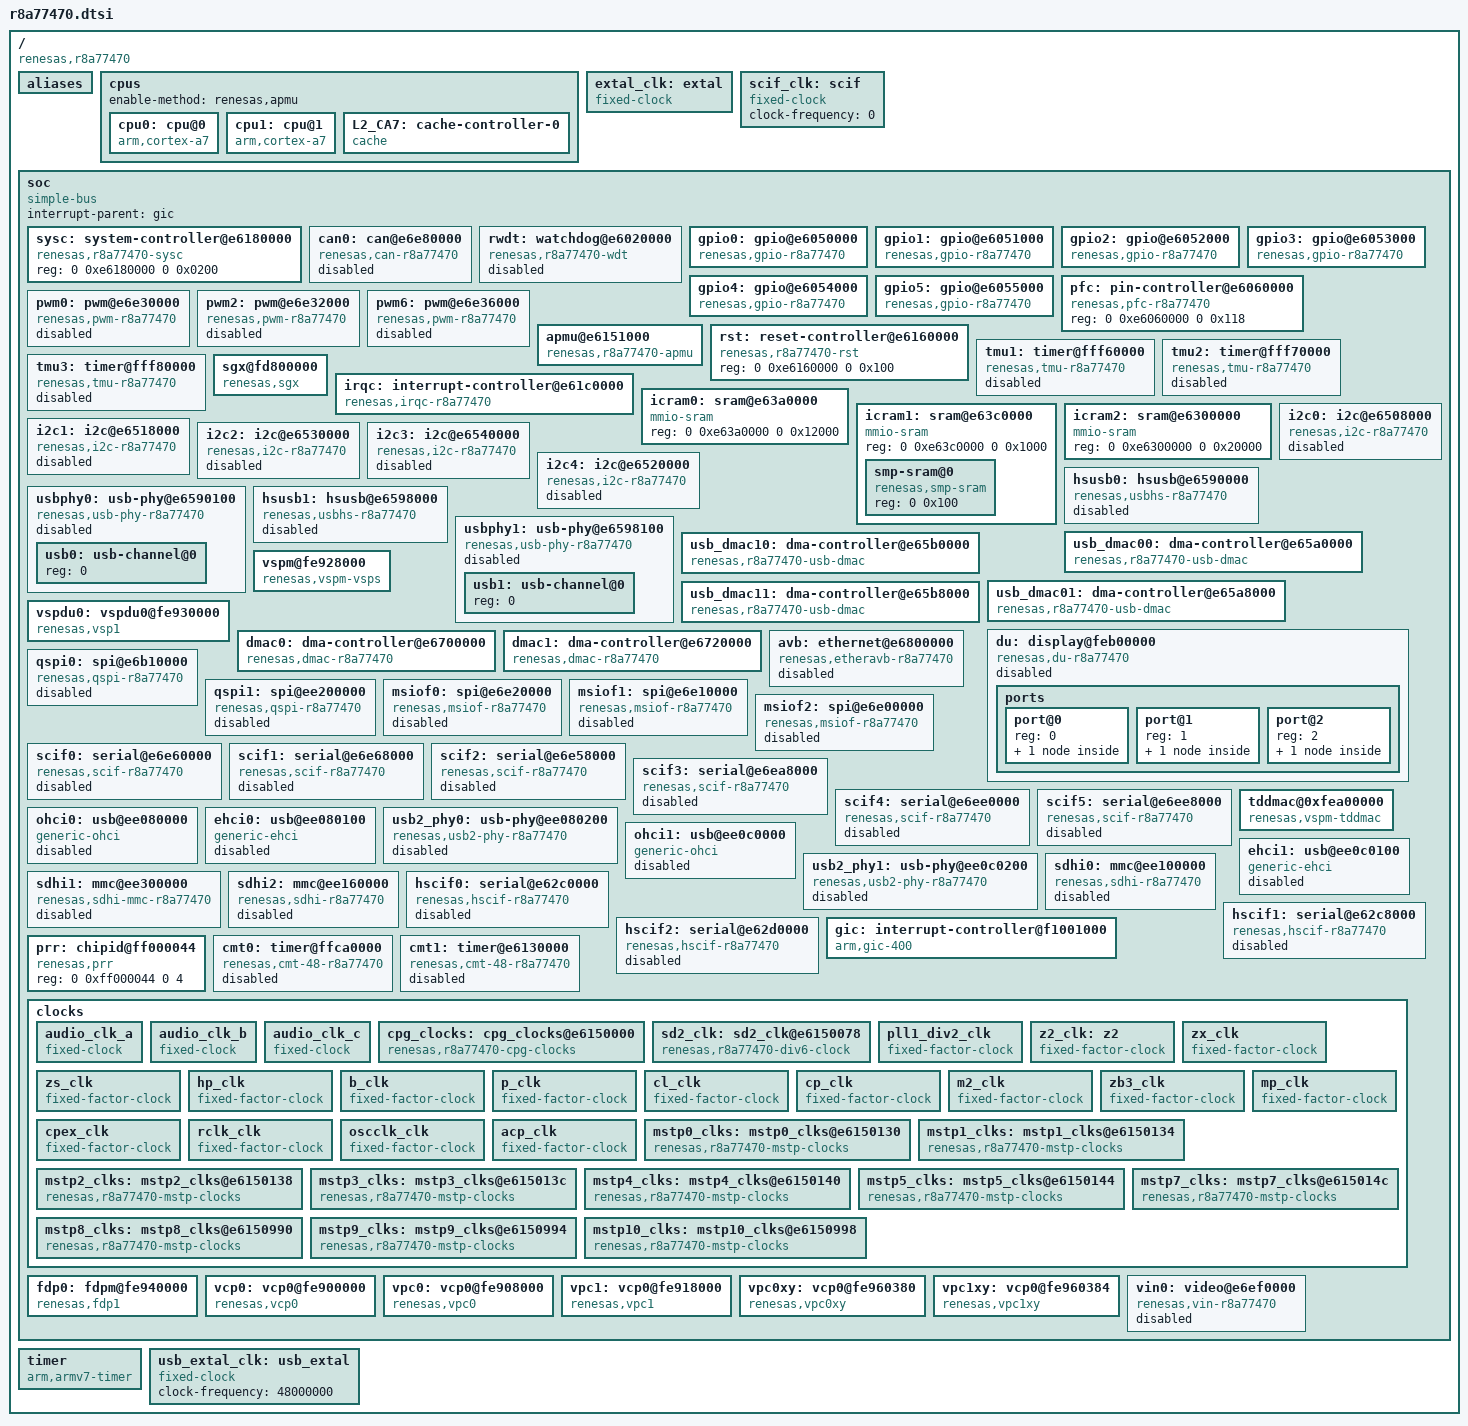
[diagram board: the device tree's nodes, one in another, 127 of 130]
// SPDX-License-Identifier: GPL-2.0
/*
 * Device Tree Source for the r8a77470 SoC
 *
 * Copyright (C) 2018 Renesas Electronics Corp.
 */

#include <dt-bindings/interrupt-controller/irq.h>
#include <dt-bindings/interrupt-controller/arm-gic.h>
#include <dt-bindings/clock/r8a77470-clock.h>
#include <dt-bindings/power/r8a77470-sysc.h>

/ {
	compatible = "renesas,r8a77470";
	#address-cells = <2>;
	#size-cells = <2>;

	aliases {
		i2c0 = &i2c0;
		i2c1 = &i2c1;
		i2c2 = &i2c2;
		i2c3 = &i2c3;
		i2c4 = &i2c4;
		spi0 = &qspi0;
		spi1 = &qspi1;
		spi2 = &msiof0;
		spi3 = &msiof1;
		spi4 = &msiof2;
		vin0 = &vin0;
	};

	cpus {
		#address-cells = <1>;
		#size-cells = <0>;
		enable-method = "renesas,apmu";

		cpu0: cpu@0 {
			device_type = "cpu";
			compatible = "arm,cortex-a7";
			reg = <0>;
			clock-frequency = <1000000000>;
			clocks = <&z2_clk>;
			power-domains = <&sysc R8A77470_PD_CA7_CPU0>;
			next-level-cache = <&L2_CA7>;
		};

		cpu1: cpu@1 {
			device_type = "cpu";
			compatible = "arm,cortex-a7";
			reg = <1>;
			clock-frequency = <1000000000>;
			clocks = <&z2_clk>;
			power-domains = <&sysc R8A77470_PD_CA7_CPU1>;
			next-level-cache = <&L2_CA7>;
		};

		L2_CA7: cache-controller-0 {
			compatible = "cache";
			cache-unified;
			cache-level = <2>;
		};
	};

	/* External root clock */
	extal_clk: extal {
		compatible = "fixed-clock";
		#clock-cells = <0>;
		/* This value must be overridden by the board. */
		clock-frequency = <0>;
		clock-output-names = "extal";
	};

	/* External SCIF clock */
	scif_clk: scif {
		compatible = "fixed-clock";
		#clock-cells = <0>;
		/* This value must be overridden by the board. */
		clock-frequency = <0>;
	};

	soc {
		compatible = "simple-bus";
		interrupt-parent = <&gic>;

		#address-cells = <2>;
		#size-cells = <2>;
		ranges;

		sysc: system-controller@e6180000 {
			compatible = "renesas,r8a77470-sysc";
			reg = <0 0xe6180000 0 0x0200>;
			#power-domain-cells = <1>;
		};

		can0: can@e6e80000 {
			compatible = "renesas,can-r8a77470";
			reg = <0 0xe6e80000 0 0x1000>;
			interrupts = <0 186 IRQ_TYPE_LEVEL_HIGH>;
			clocks = <&mstp9_clks R8A77470_CLK_CAN0>;
			clock-names = "clkp1";
			power-domains = <&sysc R8A77470_PD_ALWAYS_ON>;
			status = "disabled";
		};

		rwdt: watchdog@e6020000 {
			compatible = "renesas,r8a77470-wdt",
				     "renesas,rcar-gen2-wdt";
			reg = <0 0xe6020000 0 0x0c>;
			clocks = <&mstp4_clks R8A77470_CLK_RWDT>;
			power-domains = <&sysc R8A77470_PD_ALWAYS_ON>;
			status = "disabled";
		};

		gpio0: gpio@e6050000 {
			compatible = "renesas,gpio-r8a77470",
				     "renesas,rcar-gen2-gpio";
			reg = <0 0xe6050000 0 0x50>;
			interrupts = <GIC_SPI 4 IRQ_TYPE_LEVEL_HIGH>;
			#gpio-cells = <2>;
			gpio-controller;
			gpio-ranges = <&pfc 0 0 32>;
			#interrupt-cells = <2>;
			interrupt-controller;
			clocks = <&mstp9_clks R8A77470_CLK_GPIO0>;
			power-domains = <&sysc R8A77470_PD_ALWAYS_ON>;
		};

		gpio1: gpio@e6051000 {
			compatible = "renesas,gpio-r8a77470",
				     "renesas,rcar-gen2-gpio";
			reg = <0 0xe6051000 0 0x50>;
			interrupts = <GIC_SPI 5 IRQ_TYPE_LEVEL_HIGH>;
			#gpio-cells = <2>;
			gpio-controller;
			gpio-ranges = <&pfc 0 32 32>;
			#interrupt-cells = <2>;
			interrupt-controller;
			clocks = <&mstp9_clks R8A77470_CLK_GPIO1>;
			power-domains = <&sysc R8A77470_PD_ALWAYS_ON>;
		};

		gpio2: gpio@e6052000 {
			compatible = "renesas,gpio-r8a77470",
				     "renesas,rcar-gen2-gpio";
			reg = <0 0xe6052000 0 0x50>;
			interrupts = <GIC_SPI 6 IRQ_TYPE_LEVEL_HIGH>;
			#gpio-cells = <2>;
			gpio-controller;
			gpio-ranges = <&pfc 0 64 32>;
			#interrupt-cells = <2>;
			interrupt-controller;
			clocks = <&mstp9_clks R8A77470_CLK_GPIO2>;
			power-domains = <&sysc R8A77470_PD_ALWAYS_ON>;
		};

		gpio3: gpio@e6053000 {
			compatible = "renesas,gpio-r8a77470",
				     "renesas,rcar-gen2-gpio";
			reg = <0 0xe6053000 0 0x50>;
			interrupts = <GIC_SPI 7 IRQ_TYPE_LEVEL_HIGH>;
			#gpio-cells = <2>;
			gpio-controller;
			gpio-ranges = <&pfc 0 96 32>;
			gpio-reserved-ranges = <17 10>;
			#interrupt-cells = <2>;
			interrupt-controller;
			clocks = <&mstp9_clks R8A77470_CLK_GPIO3>;
			power-domains = <&sysc R8A77470_PD_ALWAYS_ON>;
		};

		gpio4: gpio@e6054000 {
			compatible = "renesas,gpio-r8a77470",
				     "renesas,rcar-gen2-gpio";
			reg = <0 0xe6054000 0 0x50>;
			interrupts = <GIC_SPI 8 IRQ_TYPE_LEVEL_HIGH>;
			#gpio-cells = <2>;
			gpio-controller;
			gpio-ranges = <&pfc 0 128 32>;
			#interrupt-cells = <2>;
			interrupt-controller;
			clocks = <&mstp9_clks R8A77470_CLK_GPIO4>;
			power-domains = <&sysc R8A77470_PD_ALWAYS_ON>;
		};

		gpio5: gpio@e6055000 {
			compatible = "renesas,gpio-r8a77470",
				     "renesas,rcar-gen2-gpio";
			reg = <0 0xe6055000 0 0x50>;
			interrupts = <GIC_SPI 9 IRQ_TYPE_LEVEL_HIGH>;
			#gpio-cells = <2>;
			gpio-controller;
			gpio-ranges = <&pfc 0 160 32>;
			#interrupt-cells = <2>;
			interrupt-controller;
			clocks = <&mstp9_clks R8A77470_CLK_GPIO5>;
			power-domains = <&sysc R8A77470_PD_ALWAYS_ON>;
		};

		pfc: pin-controller@e6060000 {
			compatible = "renesas,pfc-r8a77470";
			reg = <0 0xe6060000 0 0x118>;
		};

		pwm0: pwm@e6e30000 {
			compatible = "renesas,pwm-r8a77470";
			reg = <0 0xe6e30000 0 0x8>;
			#pwm-cells = <2>;
			clocks = <&mstp5_clks R8A77470_CLK_PWM>;
			power-domains = <&sysc R8A77470_PD_ALWAYS_ON>;
			status = "disabled";
		};

		pwm2: pwm@e6e32000 {
			compatible = "renesas,pwm-r8a77470";
			reg = <0 0xe6e32000 0 0x8>;
			#pwm-cells = <2>;
			clocks = <&mstp5_clks R8A77470_CLK_PWM>;
			power-domains = <&sysc R8A77470_PD_ALWAYS_ON>;
			status = "disabled";
		};

		pwm6: pwm@e6e36000 {
			compatible = "renesas,pwm-r8a77470";
			reg = <0 0xe6e36000 0 0x8>;
			#pwm-cells = <2>;
			clocks = <&mstp5_clks R8A77470_CLK_PWM>;
			power-domains = <&sysc R8A77470_PD_ALWAYS_ON>;
			status = "disabled";
		};

		apmu@e6151000 {
			compatible = "renesas,r8a77470-apmu", "renesas,apmu";
			reg = <0 0xe6151000 0 0x188>;
			cpus = <&cpu0 &cpu1>;
		};

		rst: reset-controller@e6160000 {
			compatible = "renesas,r8a77470-rst";
			reg = <0 0xe6160000 0 0x100>;
		};

		tmu1: timer@fff60000 {
			compatible = "renesas,tmu-r8a77470", "renesas,tmu";
			reg = <0 0xfff60000 0 0x30>;
			interrupts = <0 128 IRQ_TYPE_LEVEL_HIGH>,
				     <0 129 IRQ_TYPE_LEVEL_HIGH>,
				     <0 130 IRQ_TYPE_LEVEL_HIGH>;
			clocks = <&mstp1_clks R8A77470_CLK_TMU1>;
			clock-names = "fck";
			power-domains = <&sysc R8A77470_PD_ALWAYS_ON>;
			#renesas,channels = <3>;
			status = "disabled";
		};

		tmu2: timer@fff70000 {
			compatible = "renesas,tmu-r8a77470", "renesas,tmu";
			reg = <0 0xfff70000 0 0x30>;
			interrupts = <0 303 IRQ_TYPE_LEVEL_HIGH>,
				     <0 304 IRQ_TYPE_LEVEL_HIGH>,
				     <0 305 IRQ_TYPE_LEVEL_HIGH>,
				     <0 306 IRQ_TYPE_LEVEL_HIGH>;
			clocks = <&mstp1_clks R8A77470_CLK_TMU2>;
			clock-names = "fck";
			power-domains = <&sysc R8A77470_PD_ALWAYS_ON>;
			#renesas,channels = <3>;
			status = "disabled";
		};

		tmu3: timer@fff80000 {
			compatible = "renesas,tmu-r8a77470", "renesas,tmu";
			reg = <0 0xfff80000 0 0x30>;
			interrupts = <0 131 IRQ_TYPE_LEVEL_HIGH>,
				     <0 132 IRQ_TYPE_LEVEL_HIGH>,
				     <0 133 IRQ_TYPE_LEVEL_HIGH>;
			clocks = <&mstp1_clks R8A77470_CLK_TMU3>;
			clock-names = "fck";
			power-domains = <&sysc R8A77470_PD_ALWAYS_ON>;
			#renesas,channels = <3>;
			status = "disabled";
		};

		sgx@fd800000 {
			compatible = "renesas,sgx";
			reg = <0 0xfd800000 0 0x10000>;
			interrupts = <0 119 IRQ_TYPE_LEVEL_HIGH>;
			interrupt-names = "irq_sgx";
			clocks = <&mstp1_clks R8A77470_CLK_3DG>,
				<&mstp8_clks R8A77470_CLK_IPMMU_SGX>;
			clock-names = "sgx_clk", "ipmmu_clk";
			power-domains = <&sysc R8A77470_PD_SGX>;
		};

		irqc: interrupt-controller@e61c0000 {
			compatible = "renesas,irqc-r8a77470", "renesas,irqc";
			#interrupt-cells = <2>;
			interrupt-controller;
			reg = <0 0xe61c0000 0 0x200>;
			interrupts = <GIC_SPI 0 IRQ_TYPE_LEVEL_HIGH>,
				     <GIC_SPI 1 IRQ_TYPE_LEVEL_HIGH>,
				     <GIC_SPI 2 IRQ_TYPE_LEVEL_HIGH>,
				     <GIC_SPI 3 IRQ_TYPE_LEVEL_HIGH>,
				     <GIC_SPI 12 IRQ_TYPE_LEVEL_HIGH>,
				     <GIC_SPI 13 IRQ_TYPE_LEVEL_HIGH>,
				     <GIC_SPI 14 IRQ_TYPE_LEVEL_HIGH>,
				     <GIC_SPI 15 IRQ_TYPE_LEVEL_HIGH>,
				     <GIC_SPI 16 IRQ_TYPE_LEVEL_HIGH>,
				     <GIC_SPI 17 IRQ_TYPE_LEVEL_HIGH>;
			clocks = <&mstp4_clks R8A77470_CLK_IRQC>;
			power-domains = <&sysc R8A77470_PD_ALWAYS_ON>;
		};

		icram0:	sram@e63a0000 {
			compatible = "mmio-sram";
			reg = <0 0xe63a0000 0 0x12000>;
		};

		icram1:	sram@e63c0000 {
			compatible = "mmio-sram";
			reg = <0 0xe63c0000 0 0x1000>;
			#address-cells = <1>;
			#size-cells = <1>;
			ranges = <0 0 0xe63c0000 0x1000>;

			smp-sram@0 {
				compatible = "renesas,smp-sram";
				reg = <0 0x100>;
			};
		};

		icram2:	sram@e6300000 {
			compatible = "mmio-sram";
			reg = <0 0xe6300000 0 0x20000>;
		};

		i2c0: i2c@e6508000 {
			#address-cells = <1>;
			#size-cells = <0>;
			compatible = "renesas,i2c-r8a77470",
				     "renesas,rcar-gen2-i2c";
			reg = <0 0xe6508000 0 0x40>;
			interrupts = <GIC_SPI 287 IRQ_TYPE_LEVEL_HIGH>;
			clocks = <&mstp9_clks R8A77470_CLK_I2C0>;
			power-domains = <&sysc R8A77470_PD_ALWAYS_ON>;
			status = "disabled";
		};

		i2c1: i2c@e6518000 {
			#address-cells = <1>;
			#size-cells = <0>;
			compatible = "renesas,i2c-r8a77470",
				     "renesas,rcar-gen2-i2c";
			reg = <0 0xe6518000 0 0x40>;
			interrupts = <GIC_SPI 288 IRQ_TYPE_LEVEL_HIGH>;
			clocks = <&mstp9_clks R8A77470_CLK_I2C1>;
			power-domains = <&sysc R8A77470_PD_ALWAYS_ON>;
			status = "disabled";
		};

		i2c2: i2c@e6530000 {
			#address-cells = <1>;
			#size-cells = <0>;
			compatible = "renesas,i2c-r8a77470",
				     "renesas,rcar-gen2-i2c";
			reg = <0 0xe6530000 0 0x40>;
			interrupts = <GIC_SPI 286 IRQ_TYPE_LEVEL_HIGH>;
			clocks = <&mstp9_clks R8A77470_CLK_I2C2>;
			power-domains = <&sysc R8A77470_PD_ALWAYS_ON>;
			status = "disabled";
		};

		i2c3: i2c@e6540000 {
			#address-cells = <1>;
			#size-cells = <0>;
			compatible = "renesas,i2c-r8a77470",
				     "renesas,rcar-gen2-i2c";
			reg = <0 0xe6540000 0 0x40>;
			interrupts = <GIC_SPI 290 IRQ_TYPE_LEVEL_HIGH>;
			clocks = <&mstp9_clks R8A77470_CLK_I2C3>;
			power-domains = <&sysc R8A77470_PD_ALWAYS_ON>;
			status = "disabled";
		};

		i2c4: i2c@e6520000 {
			#address-cells = <1>;
			#size-cells = <0>;
			compatible = "renesas,i2c-r8a77470",
				     "renesas,rcar-gen2-i2c";
			reg = <0 0xe6520000 0 0x40>;
			interrupts = <GIC_SPI 19 IRQ_TYPE_LEVEL_HIGH>;
			clocks = <&mstp9_clks R8A77470_CLK_I2C4>;
			power-domains = <&sysc R8A77470_PD_ALWAYS_ON>;
			status = "disabled";
		};

		hsusb0: hsusb@e6590000 {
			compatible = "renesas,usbhs-r8a77470",
				     "renesas,rcar-gen2-usbhs";
			reg = <0 0xe6590000 0 0x100>;
			interrupts = <GIC_SPI 107 IRQ_TYPE_LEVEL_HIGH>;
			clocks = <&mstp7_clks R8A77470_CLK_USBHS0>;
			dmas = <&usb_dmac00 0>, <&usb_dmac00 1>,
			       <&usb_dmac10 0>, <&usb_dmac10 1>;
			dma-names = "ch0", "ch1", "ch2", "ch3";
			renesas,buswait = <4>;
			phys = <&usb0 1>;
			phy-names = "usb";
			power-domains = <&cpg_clocks>;
			status = "disabled";
		};

		usbphy0: usb-phy@e6590100 {
			compatible = "renesas,usb-phy-r8a77470",
				     "renesas,rcar-gen2-usb-phy";
			reg = <0 0xe6590100 0 0x100>;
			#address-cells = <1>;
			#size-cells = <0>;
			clocks = <&mstp7_clks R8A77470_CLK_USBHS0>;
			clock-names = "usbhs";
			power-domains = <&cpg_clocks>;
			status = "disabled";

			usb0: usb-channel@0 {
				reg = <0>;
				#phy-cells = <1>;
			};
		};

		hsusb1: hsusb@e6598000 {
			compatible = "renesas,usbhs-r8a77470",
				     "renesas,rcar-gen2-usbhs";
			reg = <0 0xe6598000 0 0x100>;
			interrupts = <GIC_SPI 291 IRQ_TYPE_LEVEL_HIGH>;
			clocks = <&mstp7_clks R8A77470_CLK_USBHS1>;
			dmas = <&usb_dmac01 0>, <&usb_dmac01 1>,
			       <&usb_dmac11 0>, <&usb_dmac11 1>;
			dma-names = "ch0", "ch1", "ch2", "ch3";
			renesas,buswait = <4>;
			/* We need to turn on usbphy0 to make usbphy1 to work */
			phys = <&usb1 1>;
			phy-names = "usb";
			power-domains = <&cpg_clocks>;
			status = "disabled";
		};

		usbphy1: usb-phy@e6598100 {
			compatible = "renesas,usb-phy-r8a77470",
				     "renesas,rcar-gen2-usb-phy";
			reg = <0 0xe6598100 0 0x100>;
			#address-cells = <1>;
			#size-cells = <0>;
			clocks = <&mstp7_clks R8A77470_CLK_USBHS1>;
			clock-names = "usbhs";
			power-domains = <&cpg_clocks>;
			status = "disabled";

			usb1: usb-channel@0 {
				reg = <0>;
				#phy-cells = <1>;
			};
		};

		usb_dmac00: dma-controller@e65a0000 {
			compatible = "renesas,r8a77470-usb-dmac",
				     "renesas,usb-dmac";
			reg = <0 0xe65a0000 0 0x100>;
			interrupts = <GIC_SPI 109 IRQ_TYPE_LEVEL_HIGH
				      GIC_SPI 109 IRQ_TYPE_LEVEL_HIGH>;
			interrupt-names = "ch0", "ch1";
			clocks = <&mstp3_clks R8A77470_CLK_USBHS_DMAC0_CH0>;
			power-domains = <&cpg_clocks>;
			#dma-cells = <1>;
			dma-channels = <2>;
		};

		usb_dmac10: dma-controller@e65b0000 {
			compatible = "renesas,r8a77470-usb-dmac",
				     "renesas,usb-dmac";
			reg = <0 0xe65b0000 0 0x100>;
			interrupts = <GIC_SPI 110 IRQ_TYPE_LEVEL_HIGH
				      GIC_SPI 110 IRQ_TYPE_LEVEL_HIGH>;
			interrupt-names = "ch0", "ch1";
			clocks = <&mstp3_clks R8A77470_CLK_USBHS_DMAC1_CH0>;
			power-domains = <&cpg_clocks>;
			#dma-cells = <1>;
			dma-channels = <2>;
		};

		usb_dmac01: dma-controller@e65a8000 {
			compatible = "renesas,r8a77470-usb-dmac",
				     "renesas,usb-dmac";
			reg = <0 0xe65a8000 0 0x100>;
			interrupts = <GIC_SPI 293 IRQ_TYPE_LEVEL_HIGH
				      GIC_SPI 293 IRQ_TYPE_LEVEL_HIGH>;
			interrupt-names = "ch0", "ch1";
			clocks = <&mstp3_clks R8A77470_CLK_USBHS_DMAC0_CH1>;
			power-domains = <&cpg_clocks>;
			#dma-cells = <1>;
			dma-channels = <2>;
		};

		usb_dmac11: dma-controller@e65b8000 {
			compatible = "renesas,r8a77470-usb-dmac",
				     "renesas,usb-dmac";
			reg = <0 0xe65b8000 0 0x100>;
			interrupts = <GIC_SPI 292 IRQ_TYPE_LEVEL_HIGH
				      GIC_SPI 292 IRQ_TYPE_LEVEL_HIGH>;
			interrupt-names = "ch0", "ch1";
			clocks = <&mstp3_clks R8A77470_CLK_USBHS_DMAC1_CH1>;
			power-domains = <&cpg_clocks>;
			#dma-cells = <1>;
			dma-channels = <2>;
		};

		vspm@fe928000 {
			compatible = "renesas,vspm-vsps", "renesas-vspm";
			reg = <0 0xfe928000 0 0x7404>;
			interrupts = <0 267 IRQ_TYPE_LEVEL_HIGH>;
			clocks = <&mstp1_clks R8A77470_CLK_VSP1_SY>;
			power-domains = <&sysc R8A77470_PD_ALWAYS_ON>;
		};

		vspdu0: vspdu0@fe930000 {
			compatible = "renesas,vsp1";
			reg = <0 0xfe930000 0 0x7404>;
			interrupts = <0 246 IRQ_TYPE_LEVEL_HIGH>;
			clocks = <&mstp1_clks R8A77470_CLK_VSP1DU0>;
			power-domains = <&sysc R8A77470_PD_ALWAYS_ON>;
		};

		du: display@feb00000 {
			compatible = "renesas,du-r8a77470";
			reg = <0 0xfeb00000 0 0x40000>;
			reg-names = "du";
			interrupts = <GIC_SPI 256 IRQ_TYPE_LEVEL_HIGH>,
				     <GIC_SPI 258 IRQ_TYPE_LEVEL_HIGH>;
			clocks = <&mstp7_clks R8A77470_CLK_DU0>,
				 <&mstp7_clks R8A77470_CLK_DU1>;
			clock-names = "du.0", "du.1";
			power-domains = <&sysc R8A77470_PD_ALWAYS_ON>;
			status = "disabled";

			vsps = <&vspdu0>;

			ports {
				#address-cells = <1>;
				#size-cells = <0>;

				port@0 {
					reg = <0>;
					du_out_rgb0: endpoint {
					};
				};
				port@1 {
					reg = <1>;
					du_out_rgb1: endpoint {
					};
				};
				port@2 {
					reg = <2>;
					du_out_lvds0: endpoint {
					};
				};
			};
		};

		dmac0: dma-controller@e6700000 {
			compatible = "renesas,dmac-r8a77470",
				     "renesas,rcar-dmac";
			reg = <0 0xe6700000 0 0x20000>;
			interrupts = <GIC_SPI 197 IRQ_TYPE_LEVEL_HIGH
				      GIC_SPI 200 IRQ_TYPE_LEVEL_HIGH
				      GIC_SPI 201 IRQ_TYPE_LEVEL_HIGH
				      GIC_SPI 202 IRQ_TYPE_LEVEL_HIGH
				      GIC_SPI 203 IRQ_TYPE_LEVEL_HIGH
				      GIC_SPI 204 IRQ_TYPE_LEVEL_HIGH
				      GIC_SPI 205 IRQ_TYPE_LEVEL_HIGH
				      GIC_SPI 206 IRQ_TYPE_LEVEL_HIGH
				      GIC_SPI 207 IRQ_TYPE_LEVEL_HIGH
				      GIC_SPI 208 IRQ_TYPE_LEVEL_HIGH
				      GIC_SPI 209 IRQ_TYPE_LEVEL_HIGH
				      GIC_SPI 210 IRQ_TYPE_LEVEL_HIGH
				      GIC_SPI 211 IRQ_TYPE_LEVEL_HIGH
				      GIC_SPI 212 IRQ_TYPE_LEVEL_HIGH
				      GIC_SPI 213 IRQ_TYPE_LEVEL_HIGH
				      GIC_SPI 214 IRQ_TYPE_LEVEL_HIGH>;
			interrupt-names = "error",
					  "ch0", "ch1", "ch2", "ch3",
					  "ch4", "ch5", "ch6", "ch7",
					  "ch8", "ch9", "ch10", "ch11",
					  "ch12", "ch13", "ch14";
			clocks = <&mstp2_clks R8A77470_CLK_SYS_DMAC0>;
			clock-names = "fck";
			power-domains = <&sysc R8A77470_PD_ALWAYS_ON>;
			#dma-cells = <1>;
			dma-channels = <15>;
		};

		dmac1: dma-controller@e6720000 {
			compatible = "renesas,dmac-r8a77470",
				     "renesas,rcar-dmac";
			reg = <0 0xe6720000 0 0x20000>;
			interrupts = <GIC_SPI 220 IRQ_TYPE_LEVEL_HIGH
				      GIC_SPI 216 IRQ_TYPE_LEVEL_HIGH
				      GIC_SPI 217 IRQ_TYPE_LEVEL_HIGH
				      GIC_SPI 218 IRQ_TYPE_LEVEL_HIGH
				      GIC_SPI 219 IRQ_TYPE_LEVEL_HIGH
				      GIC_SPI 308 IRQ_TYPE_LEVEL_HIGH
				      GIC_SPI 309 IRQ_TYPE_LEVEL_HIGH
				      GIC_SPI 310 IRQ_TYPE_LEVEL_HIGH
				      GIC_SPI 311 IRQ_TYPE_LEVEL_HIGH
				      GIC_SPI 312 IRQ_TYPE_LEVEL_HIGH
				      GIC_SPI 313 IRQ_TYPE_LEVEL_HIGH
				      GIC_SPI 314 IRQ_TYPE_LEVEL_HIGH
				      GIC_SPI 315 IRQ_TYPE_LEVEL_HIGH
				      GIC_SPI 316 IRQ_TYPE_LEVEL_HIGH
				      GIC_SPI 317 IRQ_TYPE_LEVEL_HIGH
				      GIC_SPI 318 IRQ_TYPE_LEVEL_HIGH>;
			interrupt-names = "error",
					  "ch0", "ch1", "ch2", "ch3",
					  "ch4", "ch5", "ch6", "ch7",
					  "ch8", "ch9", "ch10", "ch11",
					  "ch12", "ch13", "ch14";
			clocks = <&mstp2_clks R8A77470_CLK_SYS_DMAC1>;
			clock-names = "fck";
			power-domains = <&sysc R8A77470_PD_ALWAYS_ON>;
			#dma-cells = <1>;
			dma-channels = <15>;
		};

		avb: ethernet@e6800000 {
			compatible = "renesas,etheravb-r8a77470",
				     "renesas,etheravb-rcar-gen2";
			reg = <0 0xe6800000 0 0x7bf>;
			interrupts = <GIC_SPI 163 IRQ_TYPE_LEVEL_HIGH>;
			clocks = <&mstp8_clks R8A77470_CLK_ETHERAVB>;
			phy-mode = "gmii";
			power-domains = <&sysc R8A77470_PD_ALWAYS_ON>;
			#address-cells = <1>;
			#size-cells = <0>;
			status = "disabled";
		};

		qspi0: spi@e6b10000 {
			compatible = "renesas,qspi-r8a77470", "renesas,qspi";
			reg = <0 0xe6b10000 0 0x2c>;
			interrupts = <GIC_SPI 184 IRQ_TYPE_LEVEL_HIGH>;
			clocks = <&mstp9_clks R8A77470_CLK_QUAD_SPI0>;
			dmas = <&dmac0 0x17>, <&dmac0 0x18>,
			       <&dmac1 0x17>, <&dmac1 0x18>;
			dma-names = "tx", "rx", "tx", "rx";
			power-domains = <&sysc R8A77470_PD_ALWAYS_ON>;
			num-cs = <1>;
			#address-cells = <1>;
			#size-cells = <0>;
			status = "disabled";
		};

		qspi1: spi@ee200000 {
			compatible = "renesas,qspi-r8a77470", "renesas,qspi";
			reg = <0 0xee200000 0 0x2c>;
			interrupts = <GIC_SPI 239 IRQ_TYPE_LEVEL_HIGH>;
			clocks = <&mstp9_clks R8A77470_CLK_QUAD_SPI1>;
			dmas = <&dmac0 0xd1>, <&dmac0 0xd2>,
			       <&dmac1 0xd1>, <&dmac1 0xd2>;
			dma-names = "tx", "rx", "tx", "rx";
			power-domains = <&sysc R8A77470_PD_ALWAYS_ON>;
			num-cs = <1>;
			#address-cells = <1>;
			#size-cells = <0>;
			status = "disabled";
		};

		msiof0: spi@e6e20000 {
			compatible = "renesas,msiof-r8a77470";
			reg = <0 0xe6e20000 0 0x0064>;
			interrupts = <0 156 IRQ_TYPE_LEVEL_HIGH>;
			clocks = <&mstp0_clks R8A77470_CLK_MSIOF0>;
			dmas = <&dmac0 0x51>, <&dmac0 0x52>;
			dma-names = "tx", "rx";
			power-domains = <&sysc R8A77470_PD_ALWAYS_ON>;
			#address-cells = <1>;
			#size-cells = <0>;
			status = "disabled";
		};

		msiof1: spi@e6e10000 {
			compatible = "renesas,msiof-r8a77470";
			reg = <0 0xe6e10000 0 0x0064>;
			interrupts = <0 157 IRQ_TYPE_LEVEL_HIGH>;
			clocks = <&mstp2_clks R8A77470_CLK_MSIOF1>;
			dmas = <&dmac0 0x55>, <&dmac0 0x56>;
			dma-names = "tx", "rx";
			power-domains = <&sysc R8A77470_PD_ALWAYS_ON>;
			#address-cells = <1>;
			#size-cells = <0>;
			status = "disabled";
		};

		msiof2: spi@e6e00000 {
			compatible = "renesas,msiof-r8a77470";
			reg = <0 0xe6e00000 0 0x0064>;
			interrupts = <0 158 IRQ_TYPE_LEVEL_HIGH>;
			clocks = <&mstp2_clks R8A77470_CLK_MSIOF2>;
			dmas = <&dmac0 0x41>, <&dmac0 0x42>;
			dma-names = "tx", "rx";
			power-domains = <&sysc R8A77470_PD_ALWAYS_ON>;
			#address-cells = <1>;
			#size-cells = <0>;
			status = "disabled";
		};

		scif0: serial@e6e60000 {
			compatible = "renesas,scif-r8a77470", "renesas,scif";
			reg = <0 0xe6e60000 0 0x40>;
			interrupts = <GIC_SPI 152 IRQ_TYPE_LEVEL_HIGH>;
			clocks = <&mstp7_clks R8A77470_CLK_SCIF0>,
				 <&zs_clk>, <&scif_clk>;
			clock-names = "sci_ick", "brg_int", "scif_clk";
			dmas = <&dmac0 0x29>, <&dmac0 0x2a>,
			       <&dmac1 0x29>, <&dmac1 0x2a>;
			dma-names = "tx", "rx", "tx", "rx";
			power-domains = <&sysc R8A77470_PD_ALWAYS_ON>;
			status = "disabled";
		};

		scif1: serial@e6e68000 {
			compatible = "renesas,scif-r8a77470", "renesas,scif";
			reg = <0 0xe6e68000 0 0x40>;
			interrupts = <GIC_SPI 153 IRQ_TYPE_LEVEL_HIGH>;
			clocks = <&mstp7_clks R8A77470_CLK_SCIF1>,
				 <&zs_clk>, <&scif_clk>;
			clock-names = "sci_ick", "brg_int", "scif_clk";
			dmas = <&dmac0 0x2d>, <&dmac0 0x2e>,
			       <&dmac1 0x2d>, <&dmac1 0x2e>;
			dma-names = "tx", "rx", "tx", "rx";
			power-domains = <&sysc R8A77470_PD_ALWAYS_ON>;
			status = "disabled";
		};

		scif2: serial@e6e58000 {
			compatible = "renesas,scif-r8a77470", "renesas,scif";
			reg = <0 0xe6e58000 0 0x40>;
			interrupts = <GIC_SPI 22 IRQ_TYPE_LEVEL_HIGH>;
			clocks = <&mstp7_clks R8A77470_CLK_SCIF2>,
				 <&zs_clk>, <&scif_clk>;
			clock-names = "sci_ick", "brg_int", "scif_clk";
			dmas = <&dmac0 0x2b>, <&dmac0 0x2c>,
			       <&dmac1 0x2b>, <&dmac1 0x2c>;
			dma-names = "tx", "rx", "tx", "rx";
			power-domains = <&sysc R8A77470_PD_ALWAYS_ON>;
			status = "disabled";
		};

		scif3: serial@e6ea8000 {
			compatible = "renesas,scif-r8a77470", "renesas,scif";
			reg = <0 0xe6ea8000 0 0x40>;
			interrupts = <GIC_SPI 23 IRQ_TYPE_LEVEL_HIGH>;
			clocks = <&mstp7_clks R8A77470_CLK_SCIF3>,
				 <&zs_clk>, <&scif_clk>;
			clock-names = "sci_ick", "brg_int", "scif_clk";
			dmas = <&dmac0 0x2f>, <&dmac0 0x30>,
			       <&dmac1 0x2f>, <&dmac1 0x30>;
			dma-names = "tx", "rx", "tx", "rx";
			power-domains = <&sysc R8A77470_PD_ALWAYS_ON>;
			status = "disabled";
		};

		scif4: serial@e6ee0000 {
			compatible = "renesas,scif-r8a77470", "renesas,scif";
			reg = <0 0xe6ee0000 0 0x40>;
			interrupts = <GIC_SPI 24 IRQ_TYPE_LEVEL_HIGH>;
			clocks = <&mstp7_clks R8A77470_CLK_SCIF4>,
				 <&zs_clk>, <&scif_clk>;
			clock-names = "sci_ick", "brg_int", "scif_clk";
			dmas = <&dmac0 0xfb>, <&dmac0 0xfc>,
			       <&dmac1 0xfb>, <&dmac1 0xfc>;
			dma-names = "tx", "rx", "tx", "rx";
			power-domains = <&sysc R8A77470_PD_ALWAYS_ON>;
			status = "disabled";
		};

		scif5: serial@e6ee8000 {
			compatible = "renesas,scif-r8a77470",
				     "renesas,rcar-gen2-scif", "renesas,scif";
			reg = <0 0xe6ee8000 0 0x40>;
			interrupts = <GIC_SPI 25 IRQ_TYPE_LEVEL_HIGH>;
			clocks = <&mstp7_clks R8A77470_CLK_SCIF5>,
				 <&zs_clk>, <&scif_clk>;
			clock-names = "sci_ick", "brg_int", "scif_clk";
			dmas = <&dmac0 0xfd>, <&dmac0 0xfe>,
			       <&dmac1 0xfd>, <&dmac1 0xfe>;
			dma-names = "tx", "rx", "tx", "rx";
			power-domains = <&sysc R8A77470_PD_ALWAYS_ON>;
			status = "disabled";
		};

		tddmac@0xfea00000 {
			compatible = "renesas,vspm-tddmac","renesas,vspm";
			reg = <0 0xfea00000 0 0x200>;
			interrupts = <0 285 IRQ_TYPE_LEVEL_HIGH>;
			clocks = <&mstp1_clks R8A77470_CLK_2DDMAC>;
			power-domains = <&sysc R8A77470_PD_ALWAYS_ON>;
		};

		ohci0: usb@ee080000 {
			compatible = "generic-ohci";
			reg = <0 0xee080000 0 0x100>;
			interrupts = <GIC_SPI 108 IRQ_TYPE_LEVEL_HIGH>;
			clocks = <&mstp7_clks R8A77470_CLK_USB_EHCI_0>;
			phys = <&usb0 0>, <&usb2_phy0>;
			phy-names = "usb";
			power-domains = <&cpg_clocks>;
			status = "disabled";
		};

		ehci0: usb@ee080100 {
			compatible = "generic-ehci";
			reg = <0 0xee080100 0 0x100>;
			interrupts = <GIC_SPI 108 IRQ_TYPE_LEVEL_HIGH>;
			clocks = <&mstp7_clks R8A77470_CLK_USB_EHCI_0>;
			phys = <&usb0 0>, <&usb2_phy0>;
			phy-names = "usb";
			companion = <&ohci0>;
			power-domains = <&cpg_clocks>;
			status = "disabled";
		};

		usb2_phy0: usb-phy@ee080200 {
			compatible = "renesas,usb2-phy-r8a77470";
			reg = <0 0xee080200 0 0x700>;
			reg-names = "usb2_host";
			clocks = <&mstp7_clks R8A77470_CLK_USB_EHCI_0>;
			power-domains = <&cpg_clocks>;
			#phy-cells = <0>;
			status = "disabled";
		};

		ohci1: usb@ee0c0000 {
			compatible = "generic-ohci";
			reg = <0 0xee0c0000 0 0x100>;
			interrupts = <GIC_SPI 113 IRQ_TYPE_LEVEL_HIGH>;
			clocks = <&mstp7_clks R8A77470_CLK_USB_EHCI_1>;
			phys = <&usb0 1>, <&usb2_phy1>, <&usb1 0>;
			phy-names = "usb";
			power-domains = <&cpg_clocks>;
			status = "disabled";
		};

		ehci1: usb@ee0c0100 {
			compatible = "generic-ehci";
			reg = <0 0xee0c0100 0 0x100>;
			interrupts = <GIC_SPI 113 IRQ_TYPE_LEVEL_HIGH>;
			clocks = <&mstp7_clks R8A77470_CLK_USB_EHCI_1>;
			phys = <&usb0 1>, <&usb2_phy1>, <&usb1 0>;
			phy-names = "usb";
			companion = <&ohci1>;
			power-domains = <&cpg_clocks>;
			status = "disabled";
		};

		usb2_phy1: usb-phy@ee0c0200 {
			compatible = "renesas,usb2-phy-r8a77470";
			reg = <0 0xee0c0200 0 0x700>;
			reg-names = "usb2_host";
			clocks = <&mstp7_clks R8A77470_CLK_USB_EHCI_1>;
			power-domains = <&cpg_clocks>;
			#phy-cells = <0>;
			status = "disabled";
		};

		sdhi0: mmc@ee100000 {
			compatible = "renesas,sdhi-r8a77470",
				     "renesas,rcar-gen2-sdhi";
			reg = <0 0xee100000 0 0x328>;
			interrupts = <GIC_SPI 165 IRQ_TYPE_LEVEL_HIGH>;
			clocks = <&mstp3_clks R8A77470_CLK_SDHI0>;
			dmas = <&dmac0 0xcd>, <&dmac0 0xce>,
			       <&dmac1 0xcd>, <&dmac1 0xce>;
			dma-names = "tx", "rx", "tx", "rx";
			max-frequency = <156000000>;
			power-domains = <&sysc R8A77470_PD_ALWAYS_ON>;
			status = "disabled";
		};

		sdhi1: mmc@ee300000 {
			compatible = "renesas,sdhi-mmc-r8a77470";
			reg = <0 0xee300000 0 0x2000>;
			interrupts = <GIC_SPI 166 IRQ_TYPE_LEVEL_HIGH>;
			clocks = <&mstp3_clks R8A77470_CLK_SDHI1>;
			max-frequency = <156000000>;
			power-domains = <&sysc R8A77470_PD_ALWAYS_ON>;
			status = "disabled";
		};

		sdhi2: mmc@ee160000 {
			compatible = "renesas,sdhi-r8a77470",
				     "renesas,rcar-gen2-sdhi";
			reg = <0 0xee160000 0 0x328>;
			interrupts = <GIC_SPI 167 IRQ_TYPE_LEVEL_HIGH>;
			clocks = <&mstp3_clks R8A77470_CLK_SDHI2>;
			dmas = <&dmac0 0xd3>, <&dmac0 0xd4>,
			       <&dmac1 0xd3>, <&dmac1 0xd4>;
			dma-names = "tx", "rx", "tx", "rx";
			max-frequency = <78000000>;
			power-domains = <&sysc R8A77470_PD_ALWAYS_ON>;
			status = "disabled";
		};

		hscif0: serial@e62c0000 {
			compatible = "renesas,hscif-r8a77470", "renesas,hscif";
			reg = <0 0xe62c0000 0 96>;
			interrupts = <0 154 IRQ_TYPE_LEVEL_HIGH>;
			clocks = <&mstp7_clks R8A77470_CLK_HSCIF0>;
			clock-names = "sci_ick";
			dmas = <&dmac0 0x39>, <&dmac0 0x3a>;
			dma-names = "tx", "rx";
			power-domains = <&sysc R8A77470_PD_ALWAYS_ON>;
			status = "disabled";
		};

		hscif1: serial@e62c8000 {
			compatible = "renesas,hscif-r8a77470", "renesas,hscif";
			reg = <0 0xe62c8000 0 96>;
			interrupts = <0 155 IRQ_TYPE_LEVEL_HIGH>;
			clocks = <&mstp7_clks R8A77470_CLK_HSCIF1>;
			clock-names = "sci_ick";
			dmas = <&dmac0 0x4d>, <&dmac0 0x4e>;
			dma-names = "tx", "rx";
			power-domains = <&sysc R8A77470_PD_ALWAYS_ON>;
			status = "disabled";
		};

		hscif2: serial@e62d0000 {
			compatible = "renesas,hscif-r8a77470", "renesas,hscif";
			reg = <0 0xe62d0000 0 96>;
			interrupts = <0 21 IRQ_TYPE_LEVEL_HIGH>;
			clocks = <&mstp7_clks R8A77470_CLK_HSCIF2>;
			clock-names = "sci_ick";
			dmas = <&dmac0 0x3b>, <&dmac0 0x3c>;
			dma-names = "tx", "rx";
			power-domains = <&sysc R8A77470_PD_ALWAYS_ON>;
			status = "disabled";
		};

		gic: interrupt-controller@f1001000 {
			compatible = "arm,gic-400";
			#interrupt-cells = <3>;
			#address-cells = <0>;
			interrupt-controller;
			reg = <0 0xf1001000 0 0x1000>, <0 0xf1002000 0 0x2000>,
			      <0 0xf1004000 0 0x2000>, <0 0xf1006000 0 0x2000>;
			interrupts = <GIC_PPI 9 (GIC_CPU_MASK_SIMPLE(2) | IRQ_TYPE_LEVEL_HIGH)>;
			clocks = <&mstp4_clks R8A77470_CLK_INTC_SYS>;
			clock-names = "clk";
			power-domains = <&cpg_clocks>;
		};

		prr: chipid@ff000044 {
			compatible = "renesas,prr";
			reg = <0 0xff000044 0 4>;
		};

		cmt0: timer@ffca0000 {
			compatible = "renesas,cmt-48-r8a77470",
				     "renesas,cmt-48-gen2";
			reg = <0 0xffca0000 0 0x1004>;
			interrupts = <GIC_SPI 142 IRQ_TYPE_LEVEL_HIGH>,
				     <GIC_SPI 143 IRQ_TYPE_LEVEL_HIGH>;
			clocks = <&mstp1_clks R8A77470_CLK_CMT0>;
			clock-names = "fck";
			power-domains = <&sysc R8A77470_PD_ALWAYS_ON>;

			renesas,channels-mask = <0x60>;

			status = "disabled";
		};

		cmt1: timer@e6130000 {
			compatible = "renesas,cmt-48-r8a77470",
				     "renesas,cmt-48-gen2";
			reg = <0 0xe6130000 0 0x1004>;
			interrupts = <GIC_SPI 120 IRQ_TYPE_LEVEL_HIGH>,
				     <GIC_SPI 121 IRQ_TYPE_LEVEL_HIGH>,
				     <GIC_SPI 122 IRQ_TYPE_LEVEL_HIGH>,
				     <GIC_SPI 123 IRQ_TYPE_LEVEL_HIGH>,
				     <GIC_SPI 124 IRQ_TYPE_LEVEL_HIGH>,
				     <GIC_SPI 125 IRQ_TYPE_LEVEL_HIGH>,
				     <GIC_SPI 126 IRQ_TYPE_LEVEL_HIGH>,
				     <GIC_SPI 127 IRQ_TYPE_LEVEL_HIGH>;
			clocks = <&mstp3_clks R8A77470_CLK_CMT1>;
			clock-names = "fck";
			power-domains = <&sysc R8A77470_PD_ALWAYS_ON>;

			renesas,channels-mask = <0xff>;

			status = "disabled";
		};

		clocks {
			#address-cells = <2>;
			#size-cells = <2>;
			ranges;
			/*
			 * The external audio clocks are configured as
			 * 0 Hz fixed frequency clocks by default.
			 * Boards providing audio clocks should override them.
			 */
			audio_clk_a: audio_clk_a {
				compatible = "fixed-clock";
				#clock-cells = <0>;
				clock-frequency = <0>;
				clock-output-names = "audio_clk_a";
			};
			audio_clk_b: audio_clk_b {
				compatible = "fixed-clock";
				#clock-cells = <0>;
				clock-frequency = <0>;
				clock-output-names = "audio_clk_b";
			};
			audio_clk_c: audio_clk_c {
				compatible = "fixed-clock";
				#clock-cells = <0>;
				clock-frequency = <0>;
				clock-output-names = "audio_clk_c";
			};

			/* Special CPG clocks */
			cpg_clocks: cpg_clocks@e6150000 {
				compatible = "renesas,r8a77470-cpg-clocks",
					     "renesas,rcar-gen2-cpg-clocks";
				reg = <0 0xe6150000 0 0x1000>;
				clocks = <&extal_clk &usb_extal_clk>;
				#clock-cells = <1>;
				clock-output-names = "main", "pll0", "pll1",
						     "pll3", "lb", "qspi",
						     "sdh", "sd0", "sd1",
						     "z";
				#power-domain-cells = <0>;
			};

			/* Variable factor clocks */
			sd2_clk: sd2_clk@e6150078 {
				compatible = "renesas,r8a77470-div6-clock",
					     "renesas,cpg-div6-clock";
				reg = <0 0xe6150078 0 4>;
				clocks = <&pll1_div2_clk>;
				#clock-cells = <0>;
				clock-output-names = "sd2";
			};

			/* Fixed factor clocks */
			pll1_div2_clk: pll1_div2_clk {
				compatible = "fixed-factor-clock";
				clocks = <&cpg_clocks R8A77470_CLK_PLL1>;
				#clock-cells = <0>;
				clock-div = <2>;
				clock-mult = <1>;
				clock-output-names = "pll1_div2";
			};
			z2_clk: z2 {
				compatible = "fixed-factor-clock";
				clocks = <&cpg_clocks R8A77470_CLK_PLL0>;
				#clock-cells = <0>;
				clock-div = <1>;
				clock-mult = <1>;
				clock-output-names = "z2";
			};
			zx_clk: zx_clk {
				compatible = "fixed-factor-clock";
				clocks = <&cpg_clocks R8A77470_CLK_PLL1>;
				#clock-cells = <0>;
				clock-div = <3>;
				clock-mult = <1>;
				clock-output-names = "zx";
			};
			zs_clk: zs_clk {
				compatible = "fixed-factor-clock";
				clocks = <&cpg_clocks R8A77470_CLK_PLL1>;
				#clock-cells = <0>;
				clock-div = <6>;
				clock-mult = <1>;
				clock-output-names = "zs";
			};
			hp_clk: hp_clk {
				compatible = "fixed-factor-clock";
				clocks = <&cpg_clocks R8A77470_CLK_PLL1>;
				#clock-cells = <0>;
				clock-div = <12>;
				clock-mult = <1>;
				clock-output-names = "hp";
			};
			b_clk: b_clk {
				compatible = "fixed-factor-clock";
				clocks = <&cpg_clocks R8A77470_CLK_PLL1>;
				#clock-cells = <0>;
				clock-div = <12>;
				clock-mult = <1>;
				clock-output-names = "b";
			};
			p_clk: p_clk {
				compatible = "fixed-factor-clock";
				clocks = <&cpg_clocks R8A77470_CLK_PLL1>;
				#clock-cells = <0>;
				clock-div = <24>;
				clock-mult = <1>;
				clock-output-names = "p";
			};
			cl_clk: cl_clk {
				compatible = "fixed-factor-clock";
				clocks = <&cpg_clocks R8A77470_CLK_PLL1>;
				#clock-cells = <0>;
				clock-div = <48>;
				clock-mult = <1>;
				clock-output-names = "cl";
			};
			cp_clk: cp_clk {
				compatible = "fixed-factor-clock";
				clocks = <&cpg_clocks R8A77470_CLK_PLL1>;
				#clock-cells = <0>;
				clock-div = <48>;
				clock-mult = <1>;
				clock-output-names = "cp";
			};
			m2_clk: m2_clk {
				compatible = "fixed-factor-clock";
				clocks = <&cpg_clocks R8A77470_CLK_PLL1>;
				#clock-cells = <0>;
				clock-div = <8>;
				clock-mult = <1>;
				clock-output-names = "m2";
			};
			zb3_clk: zb3_clk {
				compatible = "fixed-factor-clock";
				clocks = <&cpg_clocks R8A77470_CLK_PLL3>;
				#clock-cells = <0>;
				clock-div = <8>;
				clock-mult = <1>;
				clock-output-names = "zb3";
			};
			mp_clk: mp_clk {
				compatible = "fixed-factor-clock";
				clocks = <&pll1_div2_clk>;
				#clock-cells = <0>;
				clock-div = <15>;
				clock-mult = <1>;
				clock-output-names = "mp";
			};
			cpex_clk: cpex_clk {
				compatible = "fixed-factor-clock";
				clocks = <&extal_clk>;
				#clock-cells = <0>;
				clock-div = <2>;
				clock-mult = <1>;
				clock-output-names = "cpex";
			};
			rclk_clk: rclk_clk {
				compatible = "fixed-factor-clock";
				clocks = <&cpg_clocks R8A77470_CLK_PLL1>;
				#clock-cells = <0>;
				clock-div = <(48 * 1024)>;
				clock-mult = <1>;
				clock-output-names = "rclk";
			};
			oscclk_clk: oscclk_clk {
				compatible = "fixed-factor-clock";
				clocks = <&cpg_clocks R8A77470_CLK_PLL1>;
				#clock-cells = <0>;
				clock-div = <(12 * 1024)>;
				clock-mult = <1>;
				clock-output-names = "oscclk";
			};
			acp_clk: acp_clk {
				compatible = "fixed-factor-clock";
				clocks = <&extal_clk>;
				#clock-cells = <0>;
				clock-div = <2>;
				clock-mult = <1>;
				clock-output-names = "acp";
			};

			/* Gate clocks */
			mstp0_clks: mstp0_clks@e6150130 {
				compatible = "renesas,r8a77470-mstp-clocks",
					     "renesas,cpg-mstp-clocks";
				reg = <0 0xe6150130 0 4>, <0 0xe6150030 0 4>;
				clocks = <&mp_clk>;
				#clock-cells = <1>;
				clock-indices = <R8A77470_CLK_MSIOF0>;
				clock-output-names = "msiof0";
			};
			mstp1_clks: mstp1_clks@e6150134 {
				compatible = "renesas,r8a77470-mstp-clocks",
					     "renesas,cpg-mstp-clocks";
				reg = <0 0xe6150134 0 4>, <0 0xe6150038 0 4>;
				clocks = <&zs_clk>, <&zs_clk>, <&p_clk>,
					 <&zs_clk>, <&zs_clk>, <&zs_clk>,
					 <&p_clk>, <&p_clk>, <&rclk_clk>,
					 <&zs_clk>, <&zs_clk>;
				#clock-cells = <1>;
				clock-indices = <
					R8A77470_CLK_VCP0 R8A77470_CLK_VPC0
					R8A77470_CLK_TMU1 R8A77470_CLK_3DG
					R8A77470_CLK_2DDMAC R8A77470_CLK_FDP1_0
					R8A77470_CLK_TMU3 R8A77470_CLK_TMU2
					R8A77470_CLK_CMT0 R8A77470_CLK_VSP1DU0
					R8A77470_CLK_VSP1_SY
				>;
				clock-output-names =
					"vcp0", "vpc0", "tmu1",
					"3dg", "2d-dmac", "fdp1-0",
					"tmu3", "tmu2", "cmt0",
					"vsp1du0", "vsp1-sy";
			};
			mstp2_clks: mstp2_clks@e6150138 {
				compatible = "renesas,r8a77470-mstp-clocks",
					     "renesas,cpg-mstp-clocks";
				reg = <0 0xe6150138 0 4>, <0 0xe6150040 0 4>;
				clocks = <&mp_clk>, <&mp_clk>, <&zs_clk>,
					 <&zs_clk>;
				#clock-cells = <1>;
				clock-indices = <
					R8A77470_CLK_MSIOF2
					R8A77470_CLK_MSIOF1
					R8A77470_CLK_SYS_DMAC1
					R8A77470_CLK_SYS_DMAC0
				>;
				clock-output-names =
					"msiof2", "msiof1", "sys-dmac1",
					"sys-dmac0";
			};
			mstp3_clks: mstp3_clks@e615013c {
				compatible = "renesas,r8a77470-mstp-clocks",
					     "renesas,cpg-mstp-clocks";
				reg = <0 0xe615013c 0 4>, <0 0xe6150048 0 4>;
				clocks = <&sd2_clk>,
					 <&cpg_clocks R8A77470_CLK_SD1>,
					 <&cpg_clocks R8A77470_CLK_SD0>,
					 <&hp_clk>, <&hp_clk>, <&rclk_clk>,
					 <&hp_clk>, <&hp_clk>;
				#clock-cells = <1>;
				clock-indices = <
					R8A77470_CLK_SDHI2
					R8A77470_CLK_SDHI1
					R8A77470_CLK_SDHI0
					R8A77470_CLK_USBHS_DMAC0_CH1
					R8A77470_CLK_USBHS_DMAC1_CH1
					R8A77470_CLK_CMT1
					R8A77470_CLK_USBHS_DMAC0_CH0
					R8A77470_CLK_USBHS_DMAC1_CH0
				>;
				clock-output-names =
					"sdhi2", "sdhi1", "sdhi0",
					"usbhs-dmac0-ch1", "usbhs-dmac1-ch1",
					"cmt1", "usbhs-dmac0-ch0",
					"usbhs-dmac1-ch0";
			};
			mstp4_clks: mstp4_clks@e6150140 {
				compatible = "renesas,r8a77470-mstp-clocks",
					     "renesas,cpg-mstp-clocks";
				reg = <0 0xe6150140 0 4>, <0 0xe615004c 0 4>;
				clocks = <&rclk_clk>, <&cp_clk>, <&zs_clk>;
				#clock-cells = <1>;
				clock-indices = <
					R8A77470_CLK_RWDT R8A77470_CLK_IRQC
					R8A77470_CLK_INTC_SYS
				>;
				clock-output-names = "rwdt", "irqc", "intc-sys";
			};
			mstp5_clks: mstp5_clks@e6150144 {
				compatible = "renesas,r8a77470-mstp-clocks",
					     "renesas,cpg-mstp-clocks";
				reg = <0 0xe6150144 0 4>, <0 0xe615003c 0 4>;
				clocks = <&zs_clk>, <&p_clk>;
				#clock-cells = <1>;
				clock-indices = <
					R8A77470_CLK_AUDIO_DMAC0
					R8A77470_CLK_PWM
				>;
				clock-output-names = "audio-dmac0", "pwm";
			};
			mstp7_clks: mstp7_clks@e615014c {
				compatible = "renesas,r8a77470-mstp-clocks",
					     "renesas,cpg-mstp-clocks";
				reg = <0 0xe615014c 0 4>, <0 0xe61501c4 0 4>;
				clocks = <&mp_clk>, <&hp_clk>, <&mp_clk>,
					 <&hp_clk>, <&zs_clk>, <&p_clk>,
					 <&p_clk>, <&zs_clk>, <&zs_clk>,
					 <&p_clk>, <&p_clk>, <&p_clk>,
					 <&p_clk>, <&zx_clk>, <&zx_clk>,
					 <&zx_clk>, <&zx_clk>;
				#clock-cells = <1>;
				clock-indices = <
					R8A77470_CLK_USB_EHCI_0
					R8A77470_CLK_USBHS0
					R8A77470_CLK_USB_EHCI_1
					R8A77470_CLK_USBHS1 R8A77470_CLK_HSCIF2
					R8A77470_CLK_SCIF5 R8A77470_CLK_SCIF4
					R8A77470_CLK_HSCIF1 R8A77470_CLK_HSCIF0
					R8A77470_CLK_SCIF3 R8A77470_CLK_SCIF2
					R8A77470_CLK_SCIF1 R8A77470_CLK_SCIF0
					R8A77470_CLK_DU1 R8A77470_CLK_DU0
					R8A77470_CLK_LVDS R8A77470_CLK_DVE
				>;
				clock-output-names =
					"usb-ehci-0", "usbhs-0", "usb-ehci-1",
					"usbhs-1", "hscif2", "scif5", "scif4",
					"hscif1", "hscif0", "scif3", "scif2",
					"scif1", "scif0", "du1", "du0",
					"lvds0", "dvenc";
			};
			mstp8_clks: mstp8_clks@e6150990 {
				compatible = "renesas,r8a77470-mstp-clocks",
					     "renesas,cpg-mstp-clocks";
				reg = <0 0xe6150990 0 4>, <0 0xe61509a0 0 4>;
				clocks = <&zx_clk>, <&zx_clk>, <&zs_clk>,
					 <&zs_clk>, <&hp_clk>, <&p_clk>;
				#clock-cells = <1>;
				clock-indices = <
					R8A77470_CLK_IPMMU_SGX R8A77470_CLK_DVD
					R8A77470_CLK_VIN1 R8A77470_CLK_VIN0
					R8A77470_CLK_ETHERAVB R8A77470_CLK_ETHER
				>;
				clock-output-names =
					"ipmmu-sgx", "dvdec", "vin1", "vin0",
					"etheravb", "ether";
			};
			mstp9_clks: mstp9_clks@e6150994 {
				compatible = "renesas,r8a77470-mstp-clocks",
					     "renesas,cpg-mstp-clocks";
				reg = <0 0xe6150994 0 4>, <0 0xe61509a4 0 4>;
				clocks = <&cp_clk>, <&cp_clk>, <&cp_clk>,
					 <&cp_clk>, <&cp_clk>, <&cp_clk>,
					 <&p_clk>, <&p_clk>,
					 <&cpg_clocks R8A77470_CLK_QSPI>,
					 <&cpg_clocks R8A77470_CLK_QSPI>,
					 <&hp_clk>, <&hp_clk>, <&hp_clk>,
					 <&hp_clk>, <&hp_clk>;
				#clock-cells = <1>;
				clock-indices = <
					R8A77470_CLK_GPIO5 R8A77470_CLK_GPIO4
					R8A77470_CLK_GPIO3 R8A77470_CLK_GPIO2
					R8A77470_CLK_GPIO1 R8A77470_CLK_GPIO0
					R8A77470_CLK_CAN1 R8A77470_CLK_CAN0
					R8A77470_CLK_QUAD_SPI1
					R8A77470_CLK_QUAD_SPI0
					R8A77470_CLK_I2C4 R8A77470_CLK_I2C3
					R8A77470_CLK_I2C2 R8A77470_CLK_I2C1
					R8A77470_CLK_I2C0
				>;
				clock-output-names =
					"gpio5", "gpio4", "gpio3", "gpio2",
					"gpio1", "gpio0", "can1", "can0",
					"qspi_mod-1", "qspi_mod-0", "i2c4",
					"i2c3", "i2c2", "i2c1", "i2c0";
			};
			mstp10_clks: mstp10_clks@e6150998 {
				compatible = "renesas,r8a77470-mstp-clocks",
					     "renesas,cpg-mstp-clocks";
				reg = <0 0xe6150998 0 4>, <0 0xe61509a8 0 4>;
				clocks = <&p_clk>, <&p_clk>, <&p_clk>, <&p_clk>,
					 <&p_clk>, <&p_clk>, <&p_clk>, <&p_clk>,
					 <&p_clk>, <&p_clk>, <&p_clk>, <&p_clk>,
					 <&mstp10_clks R8A77470_CLK_SCU_ALL>,
					 <&mstp10_clks R8A77470_CLK_SCU_ALL>,
					 <&mstp10_clks R8A77470_CLK_SCU_ALL>,
					 <&mstp10_clks R8A77470_CLK_SCU_ALL>,
					 <&mstp10_clks R8A77470_CLK_SCU_ALL>,
					 <&mstp10_clks R8A77470_CLK_SCU_ALL>,
					 <&mstp10_clks R8A77470_CLK_SCU_ALL>,
					 <&mstp10_clks R8A77470_CLK_SCU_ALL>,
					 <&mstp10_clks R8A77470_CLK_SCU_ALL>,
					 <&mstp10_clks R8A77470_CLK_SCU_ALL>;
				#clock-cells = <1>;
				clock-indices = <
					R8A77470_CLK_SSI_ALL R8A77470_CLK_SSI9
					R8A77470_CLK_SSI8 R8A77470_CLK_SSI7
					R8A77470_CLK_SSI6 R8A77470_CLK_SSI5
					R8A77470_CLK_SSI4 R8A77470_CLK_SSI3
					R8A77470_CLK_SSI2 R8A77470_CLK_SSI1
					R8A77470_CLK_SSI0 R8A77470_CLK_SCU_ALL
					R8A77470_CLK_SCU_DVC1
					R8A77470_CLK_SCU_DVC0
					R8A77470_CLK_SCU_CTU1_MIX1
					R8A77470_CLK_SCU_CTU0_MIX0
					R8A77470_CLK_SCU_SRC6
					R8A77470_CLK_SCU_SRC5
					R8A77470_CLK_SCU_SRC4
					R8A77470_CLK_SCU_SRC3
					R8A77470_CLK_SCU_SRC2
					R8A77470_CLK_SCU_SRC1
				>;
				clock-output-names =
					"ssi-all", "ssi9", "ssi8", "ssi7",
					"ssi6",	"ssi5",	"ssi4",	"ssi3",	"ssi2",
					"ssi1",	"ssi0",	"scu-all", "scu-dvc1",
					"scu-dvc0", "scu-ctu1-mix1",
					"scu-ctu0-mix0", "scu-src6", "scu-src5",
					"scu-src4", "scu-src3", "scu-src2",
					"scu-src1";
			};
		};

		fdp0: fdpm@fe940000 {
			compatible = "renesas,fdp1";
			reg = <0 0xfe940000 0 0x2400>;
			interrupts = <0 262 IRQ_TYPE_LEVEL_HIGH>;
			clocks = <&mstp1_clks R8A77470_CLK_FDP1_0>;
			power-domains = <&sysc R8A77470_PD_ALWAYS_ON>;
		};

		vcp0: vcp0@fe900000 {
			compatible = "renesas,vcp0";
			reg = <0 0xfe900000 0 0x200>, <0 0xfe900200 0 0x200>;
			interrupts = <0 258 IRQ_TYPE_LEVEL_HIGH>,
				<0 259 IRQ_TYPE_LEVEL_HIGH>;
			clocks = <&mstp1_clks R8A77470_CLK_VCP0>;
			power-domains = <&sysc R8A77470_PD_ALWAYS_ON>;
			renesas,#ch = <0>;
		};

		vpc0: vcp0@fe908000 {
			compatible = "renesas,vpc0";
			reg = <0 0xfe908000 0 0x90>;
			clocks = <&mstp1_clks R8A77470_CLK_VPC0>;
			power-domains = <&sysc R8A77470_PD_ALWAYS_ON>;
			renesas,#ch = <0>;
		};

		vpc1: vcp0@fe918000 {
			compatible = "renesas,vpc1";
			reg = <0 0xfe918000 0 0x90>;
			/* clocks = <&mstp1_clks R8A77470_CLK_VPC1>; */
			power-domains = <&sysc R8A77470_PD_ALWAYS_ON>;
			renesas,#ch = <0>;
		};

		vpc0xy: vcp0@fe960380 {
			compatible = "renesas,vpc0xy";
			reg = <0 0xfe960380 0 0x4>;
			/* clocks = <&mstp1_clks R8A77470_CLK_VPC0>; */
			power-domains = <&sysc R8A77470_PD_ALWAYS_ON>;
			renesas,#ch = <0>;
		};

		vpc1xy: vcp0@fe960384 {
			compatible = "renesas,vpc1xy";
			reg = <0 0xfe960384 0 0x4>;
			/* #clocks = <&mstp1_clks R8A77470_CLK_VPC1>; */
			power-domains = <&sysc R8A77470_PD_ALWAYS_ON>;
			renesas,#ch = <0>;
		};

		vin0: video@e6ef0000 {
			compatible = "renesas,vin-r8a77470";
			reg = <0 0xe6ef0000 0 0x1000>;
			interrupts = <0 188 IRQ_TYPE_LEVEL_HIGH>;
			clocks = <&mstp8_clks R8A77470_CLK_VIN0>;
			power-domains = <&sysc R8A77470_PD_ALWAYS_ON>;
			status = "disabled";
		};
	};

	timer {
		compatible = "arm,armv7-timer";
		interrupts-extended = <&gic GIC_PPI 13 (GIC_CPU_MASK_SIMPLE(2) | IRQ_TYPE_LEVEL_LOW)>,
				      <&gic GIC_PPI 14 (GIC_CPU_MASK_SIMPLE(2) | IRQ_TYPE_LEVEL_LOW)>,
				      <&gic GIC_PPI 11 (GIC_CPU_MASK_SIMPLE(2) | IRQ_TYPE_LEVEL_LOW)>,
				      <&gic GIC_PPI 10 (GIC_CPU_MASK_SIMPLE(2) | IRQ_TYPE_LEVEL_LOW)>;
	};

	/* External USB clock - can be overridden by the board */
	usb_extal_clk: usb_extal {
		compatible = "fixed-clock";
		#clock-cells = <0>;
		clock-frequency = <48000000>;
	};
};
